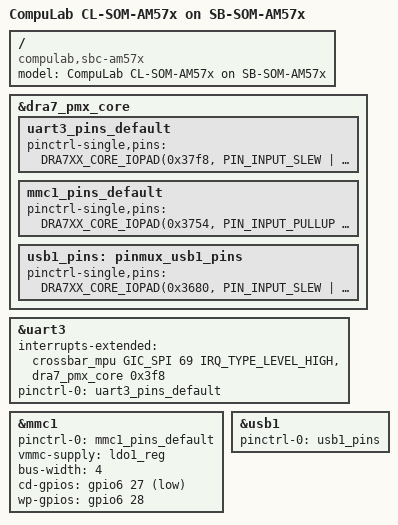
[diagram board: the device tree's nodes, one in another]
/*
 * Support for CompuLab SBC-AM57x single board computer
 *
 * Copyright (C) 2015 CompuLab Ltd. - http://www.compulab.co.il/
 * Author: Dmitry Lifshitz <lifshitz@compulab.co.il>
 *
 * This program is free software; you can redistribute it and/or modify it
 * under the terms of the GNU General Public License version 2 as published by
 * the Free Software Foundation.
 */

#include "am57xx-cl-som-am57x.dts"
#include "compulab-sb-som.dtsi"

/ {
	model = "CompuLab CL-SOM-AM57x on SB-SOM-AM57x";
	compatible = "compulab,sbc-am57x", "compulab,cl-som-am57x", "ti,am5728", "ti,dra742", "ti,dra74", "ti,dra7";
};

&dra7_pmx_core {
	uart3_pins_default: uart3_pins_default {
		pinctrl-single,pins = <
			DRA7XX_CORE_IOPAD(0x37f8, PIN_INPUT_SLEW | MUX_MODE2)	/* uart2_ctsn.uart3_rxd */
			DRA7XX_CORE_IOPAD(0x37fc, PIN_INPUT_SLEW | MUX_MODE1)	/* uart2_rtsn.uart3_txd */
		>;
	};

	mmc1_pins_default: mmc1_pins_default {
		pinctrl-single,pins = <
			DRA7XX_CORE_IOPAD(0x3754, PIN_INPUT_PULLUP | MUX_MODE0) /* mmc1_clk.clk */
			DRA7XX_CORE_IOPAD(0x3758, PIN_INPUT_PULLUP | MUX_MODE0)	/* mmc1_cmd.cmd */
			DRA7XX_CORE_IOPAD(0x375c, PIN_INPUT_PULLUP | MUX_MODE0) /* mmc1_dat0.dat0 */
			DRA7XX_CORE_IOPAD(0x3760, PIN_INPUT_PULLUP | MUX_MODE0) /* mmc1_dat1.dat1 */
			DRA7XX_CORE_IOPAD(0x3764, PIN_INPUT_PULLUP | MUX_MODE0) /* mmc1_dat2.dat2 */
			DRA7XX_CORE_IOPAD(0x3768, PIN_INPUT_PULLUP | MUX_MODE0) /* mmc1_dat3.dat3 */
			DRA7XX_CORE_IOPAD(0x376c, PIN_INPUT | MUX_MODE14)	/* mmc1_sdcd.gpio6_27 */
			DRA7XX_CORE_IOPAD(0x377c, PIN_INPUT | MUX_MODE14)	/* mmc1_sdwp.gpio6_28 */
		>;
	};

	usb1_pins: pinmux_usb1_pins {
		pinctrl-single,pins = <
			DRA7XX_CORE_IOPAD(0x3680, PIN_INPUT_SLEW | MUX_MODE0) /* usb1_drvvbus */
		>;
	};
};

&uart3 {
	status = "okay";
	interrupts-extended = <&crossbar_mpu GIC_SPI 69 IRQ_TYPE_LEVEL_HIGH>,
			      <&dra7_pmx_core 0x3f8>;

	pinctrl-names = "default";
	pinctrl-0 = <&uart3_pins_default>;
};

&mmc1 {
	status = "okay";

	pinctrl-names = "default";
	pinctrl-0 = <&mmc1_pins_default>;

	vmmc-supply = <&ldo1_reg>;
	bus-width = <4>;
	cd-gpios = <&gpio6 27 GPIO_ACTIVE_LOW>;
	wp-gpios = <&gpio6 28 GPIO_ACTIVE_HIGH>;
};

&usb1 {
	pinctrl-names = "default";
	pinctrl-0 = <&usb1_pins>;
};
